# ESP32S31_RADIO register map
Vendor: Espressif; Series: ESP32-S31; File version: 3.52
Registers are 32-bit, read-write, no defined reset value unless marked. A register's access mark holds for its fields unless they carry their own. Offsets are from the block's base; [hi:lo] are bit positions.

## ZBBB_RADIO_CONTROL — Independently bounded words in the ZBBB window touched by complete Bluetooth baseband receive-setup and reset-idle leaves. Names describe only those exact operations; they do not claim that the physical block is owned exclusively by Bluetooth or assign a wider ZBBB protocol meaning.
Base 0x20102C00
0x00 RX_SETUP_IMAGE — Project-assigned name. bt_bb_rx_set preserves the low 12 bits and replaces bits 31:12 with the finite image 0x001CB; after the shared receive prefix, bt_bb_v2_init_cmplx(1) independently replaces the same field with 0x0019F.
  [31:12] BITS_12_31_OPAQUE — Opaque: meaning not established.
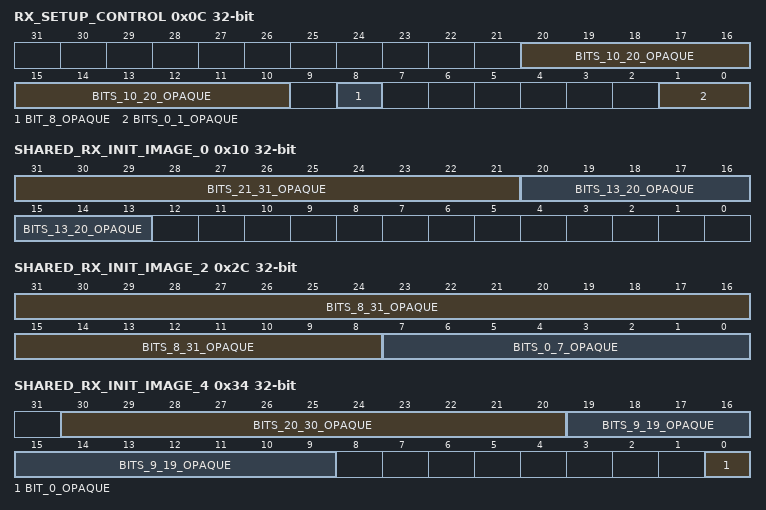
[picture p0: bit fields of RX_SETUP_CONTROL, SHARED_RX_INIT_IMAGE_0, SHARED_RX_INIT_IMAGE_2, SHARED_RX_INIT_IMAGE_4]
0x0C RX_SETUP_CONTROL — Project-assigned name. bt_bb_rx_set clears bit 8 and the low two-bit field through separate fresh-read RMW operations; the complete shared receive initializer independently replaces bits 10:20.
  [20:10] BITS_10_20_OPAQUE — Opaque: meaning not established. The complete shared receive initializer replaces bits 10:20 with the finite image 0x79C.
  [8] BIT_8_OPAQUE — Opaque: meaning not established.
  [1:0] BITS_0_1_OPAQUE — Opaque: meaning not established.
0x10 SHARED_RX_INIT_IMAGE_0 — Project-assigned name. The complete shared receive initializer replaces two disjoint positional fields with finite images while preserving every other bit.
  [31:21] BITS_21_31_OPAQUE — Opaque: meaning not established. The complete initializer replaces bits 21:31 with the finite image 0x792.
  [20:13] BITS_13_20_OPAQUE — Opaque: meaning not established. The complete initializer replaces bits 13:20 with the finite image 0xA6.
0x14 SHARED_RX_INIT_CONTROL_0 — Project-assigned name. The complete shared receive initializer clears one positional control bit and preserves the remainder of the word.
  [1] BIT_1_OPAQUE — Opaque: meaning not established. The complete initializer clears bit 1.
0x18 SHARED_RX_INIT_IMAGE_1 — Project-assigned name. The complete shared receive initializer replaces the low eleven bits with one finite image.
  [10:0] BITS_0_10_OPAQUE — Opaque: meaning not established. The complete initializer replaces bits 0:10 with the finite image 0x7A6.
0x28 SHARED_RX_INIT_CONTROL_1 — Project-assigned name. The complete shared receive initializer sets one positional control bit and preserves the remainder of the word.
  [30] BIT_30_OPAQUE — Opaque: meaning not established. The complete initializer sets bit 30.
0x2C SHARED_RX_INIT_IMAGE_2 — Project-assigned name. The complete shared receive initializer replaces the high twenty-four bits and low byte through two disjoint fresh-read updates.
  [31:8] BITS_8_31_OPAQUE — Opaque: meaning not established. The complete initializer replaces bits 8:31 with the finite image 0x07A120.
  [7:0] BITS_0_7_OPAQUE — Opaque: meaning not established. The complete initializer replaces bits 0:7 with the finite image 0xF1.
0x30 SHARED_RX_INIT_IMAGE_3 — Project-assigned name. The complete shared receive initializer replaces the high twenty-four bits with one finite image.
  [31:8] BITS_8_31_OPAQUE — Opaque: meaning not established. The complete initializer replaces bits 8:31 with the finite image 0xF85EDF.
0x34 SHARED_RX_INIT_IMAGE_4 — Project-assigned name. The complete shared receive initializer replaces three disjoint positional fields with finite images.
  [30:20] BITS_20_30_OPAQUE — Opaque: meaning not established. The complete initializer replaces bits 20:30 with the finite image 0x7E1.
  [19:9] BITS_9_19_OPAQUE — Opaque: meaning not established. The complete initializer replaces bits 9:19 with the finite image 0x7ED.
  [0] BIT_0_OPAQUE — Opaque: meaning not established. The complete initializer sets bit 0.
0x38 SOFTWARE_RESET_IDLE_STATUS ro — Project-assigned name. bbmac_idle_for_swrst reports idle only when the observed low three-bit image equals one.
  [2:0] LOW_3_REQUIRED_IMAGE — Project-assigned name. The reset-idle predicate compares this exact field with the finite image 1.
